# pse84_a0 register map
Vendor: Infineon Technologies; Series: PSE84_A0; File version: 1.0
CPU: CM33 r0p1, little endian, MPU, FPU, VTOR, 3 interrupt priority bits
Registers are 32-bit, read-write, reset 0x0 unless marked. A register's access mark holds for its fields unless they carry their own. Offsets are from the block's base; [hi:lo] are bit positions; lines under a group give offsets from that group; {n}, {i} and the like mark numbered series; <NAME> marks a mode.

## USBHS (part 3 of 7) — Regmap for both Subsystem and Controller IP
Base 0x44900000
0x00 DWC_OTG_INTREG group — Internal register map
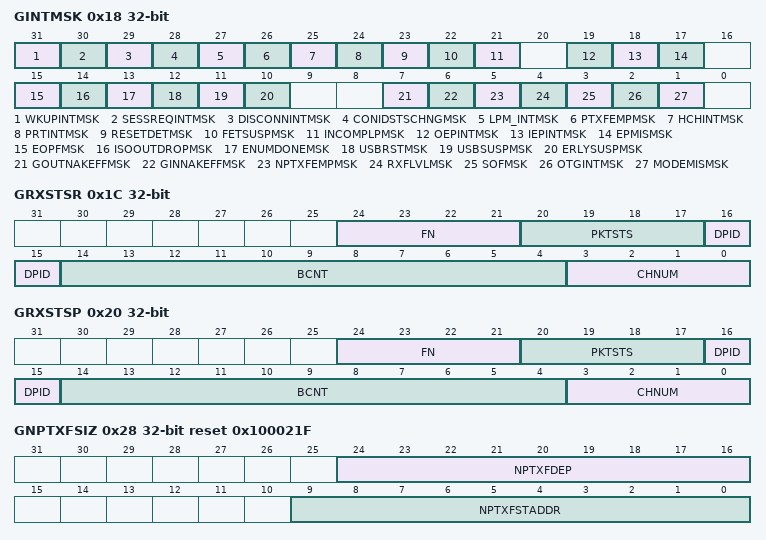
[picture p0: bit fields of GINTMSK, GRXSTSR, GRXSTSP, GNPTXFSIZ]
  0x18 GINTMSK — This register works with the Interrupt Register (GINTSTS) to interrupt the application. When an interrupt bit is masked, the interrupt associated with that bit is not generated. However, the GINTSTS register bit corresponding to that interrupt is still set. Note: The fields of this register change depending on host or device mode.
    [31] WKUPINTMSK — Mode: Host and Device Resume/Remote Wakeup Detected Interrupt Mask (WkUpIntMsk) The WakeUp bit is used for LPM state wake up in a way similar to that of wake up in suspend state.
      0=MASK (Resume or Remote Wakeup Detected Interrupt Mask); 1=NOMASK (Unmask Resume Remote Wakeup Detected Interrupt)
    [30] SESSREQINTMSK — Mode: Host and Device Session Request/New Session Detected Interrupt Mask (SessReqIntMsk)
      0=MASK (Session Request or New Session Detected Interrupt Mask); 1=NOMASK (No Session Request or New Session Detected Interrupt Mask)
    [29] DISCONNINTMSK — Mode: Host and Device Disconnect Detected Interrupt Mask (DisconnIntMsk)
      0=MASK (Disconnect Detected Interrupt Mask); 1=NOMASK (No Disconnect Detected Interrupt Mask)
    [28] CONIDSTSCHNGMSK — Mode: Host and Device Connector ID Status Change Mask (ConIDStsChngMsk)
      0=MASK (Connector ID Status Change Mask); 1=NOMASK (No Connector ID Status Change Mask)
    [27] LPM_INTMSK — Mode: Host and Device LPM Transaction Received Interrupt (LPM_Int) LPM Transaction received interrupt Mask
      0=MASK (LPM Transaction received interrupt Mask); 1=NOMASK (No LPM Transaction received interrupt Mask)
    [26] PTXFEMPMSK — Mode: Host only Periodic TxFIFO Empty Mask (PTxFEmpMsk)
      0=MASK (Periodic TxFIFO Empty Mask); 1=NOMASK (No Periodic TxFIFO Empty Mask)
    [25] HCHINTMSK — Mode: Host only Host Channels Interrupt Mask (HChIntMsk)
      0=MASK (Host Channels Interrupt Mask); 1=NOMASK (No Host Channels Interrupt Mask)
    [24] PRTINTMSK — Mode: Host only Host Port Interrupt Mask (PrtIntMsk)
      0=MASK (Host Port Interrupt Mask); 1=NOMASK (No Host Port Interrupt Mask)
    [23] RESETDETMSK — Mode: Device only Reset detected Interrupt Mask (ResetDetMsk)
      0=MASK (Reset detected Interrupt Mask); 1=NOMASK (No Reset detected Interrupt Mask)
    [22] FETSUSPMSK — Mode: Device only Data Fetch Suspended Mask (FetSuspMsk)
      0=MASK (Data Fetch Suspended Mask); 1=NOMASK (No Data Fetch Suspended Mask)
    [21] INCOMPLPMSK — Incomplete Periodic Transfer Mask (incomplPMsk) Mode: Host only Incomplete Isochronous OUT Transfer Interrupt Mask (incompISOOUTMsk) Mode: Device only
      0=MASK (<ct:cbc:1:0><br>Host mode: </ct>Incomplete Periodic Transfer Mask<ct:cbc:1:0><br>Device mode: Incomplete Isochronous OUT Transfer Mask</ct>); 1=NOMASK (<ct:cbc:1:0><br>Host mode: </ct>No Incomplete Periodic Transfer Mask<ct:cbc:1:0><br>Device mode: No Incomplete Isochronous OUT Transfer Mask</ct>)
    [19] OEPINTMSK — Mode: Device only OUT Endpoints Interrupt Mask (OEPIntMsk)
      0=MASK (OUT Endpoints Interrupt Mask); 1=NOMASK (No OUT Endpoints Interrupt Mask)
    [18] IEPINTMSK — Mode: Device only IN Endpoints Interrupt Mask (IEPIntMsk)
      0=MASK (IN Endpoints Interrupt Mask); 1=NOMASK (No IN Endpoints Interrupt Mask)
    [17] EPMISMSK — Mode: Device only Endpoint Mismatch Interrupt Mask (EPMisMsk)
      0=MASK (Endpoint Mismatch Interrupt Mask); 1=NOMASK (No Endpoint Mismatch Interrupt Mask)
    [15] EOPFMSK — Mode: Device only End of Periodic Frame Interrupt Mask (EOPFMsk)
      0=MASK (End of Periodic Frame Interrupt Mask); 1=NOMASK (No End of Periodic Frame Interrupt Mask)
    [14] ISOOUTDROPMSK — Mode: Device only Isochronous OUT Packet Dropped Interrupt Mask (ISOOutDropMsk)
      0=MASK (Isochronous OUT Packet Dropped Interrupt Mask); 1=NOMASK (No Isochronous OUT Packet Dropped Interrupt Mask)
    [13] ENUMDONEMSK — Mode: Device only Enumeration Done Mask (EnumDoneMsk)
      0=MASK (Enumeration Done Mask); 1=NOMASK (No Enumeration Done Mask)
    [12] USBRSTMSK — Mode: Device only USB Reset Mask (USBRstMsk)
      0=MASK (USB Reset Mask); 1=NOMASK (No USB Reset Mask)
    [11] USBSUSPMSK — Mode: Device only USB Suspend Mask (USBSuspMsk)
      0=MASK (USB Suspend Mask); 1=NOMASK (No USB Suspend Mask)
    [10] ERLYSUSPMSK — Mode: Device only Early Suspend Mask (ErlySuspMsk)
      0=MASK (Early Suspend Mask); 1=NOMASK (No Early Suspend Mask)
    [7] GOUTNAKEFFMSK — Mode: Device only Global OUT NAK Effective Mask (GOUTNakEffMsk)
      0=MASK (Global OUT NAK Effective Mask); 1=NOMASK (No Global OUT NAK Effective Mask)
    [6] GINNAKEFFMSK — Mode: Device only, Global Non-periodic IN NAK Effective Mask (GINNakEffMsk)
      0=MASK (Global Non-periodic IN NAK Effective Mask); 1=NOMASK (No Global Non-periodic IN NAK Effective Mask)
    [5] NPTXFEMPMSK — Mode: Host and Device Non-periodic TxFIFO Empty Mask (NPTxFEmpMsk)
      0=MASK (Non-periodic TxFIFO Empty Mask); 1=NOMASK (No Non-periodic TxFIFO Empty Mask)
    [4] RXFLVLMSK — Mode: Host and Device Receive FIFO Non-Empty Mask (RxFLvlMsk)
      0=MASK (Receive FIFO Non-Empty Mask); 1=NOMASK (No Receive FIFO Non-Empty Mask)
    [3] SOFMSK — Mode: Host and Device Start of (micro)Frame Mask (SofMsk)
      0=MASK (Start of Frame Mask); 1=NOMASK (No Start of Frame Mask)
    [2] OTGINTMSK — Mode: Host and Device OTG Interrupt Mask (OTGIntMsk)
      0=MASK (OTG Interrupt Mask); 1=NOMASK (No OTG Interrupt Mask)
    [1] MODEMISMSK — Mode: Host and Device Mode Mismatch Interrupt Mask (ModeMisMsk)
      0=MASK (Mode Mismatch Interrupt Mask); 1=NOMASK (No Mode Mismatch Interrupt Mask)
  0x1C GRXSTSR ro — A read to the Receive Status Debug Read register returns the contents of the top of the Receive FIFO. The receive status contents must be interpreted differently in Host and Device modes. The core ignores the receive status read when the receive FIFO is empty and returns a value of 32'h0000_0000. Note: - Use of these fields vary based on whether the core is functioning as a host or a device. - Do not read this register's reset value before configuring the core because the read value is 'X' in the simulation.
    [24:21] FN — Mode: Device only Frame Number (FN) This is the least significant 4 bits of the (micro)Frame number in which the packet is received on the USB. This field is supported only when isochronous OUT endpoints are supported.
    [20:17] PKTSTS
      7=CHHALT (Channel halted in host mode (triggers an interrupt)); 4=DSETUPCOM (SETUP transaction completed <ct:DWC_DESIGN_ID==0>in device mode </ct>(triggers an interrupt)); 6=DSETUPRX (SETUP data packet received<ct:DWC_DESIGN_ID==0> in device mode</ct>); 5=DTTOG (Data toggle error (triggers an interrupt) in host mode); 2=INOUTDPRX (<ct:DWC_DESIGN_ID==0>IN data packet received in host mode and </ct>OUT data packet received <ct:DWC_DESIGN_ID==0>in device mode</ct>); 3=INOUTTRCOM (IN or OUT transfer completed <ct:DWC_DESIGN_ID==0>in both host and device mode </ct>(triggers an interrupt)); 1=OUTNAK (Global OUT NAK <ct:DWC_DESIGN_ID==0>in device mode </ct>(triggers an interrupt))
    [16:15] DPID — Data PID (DPID) In host mode, indicates the Data PID of the received packet. In device mode, indicates the Data PID of the received OUT data packet. - 2'b00: DATA0 - 2'b10: DATA1 - 2'b01: DATA2 - 2'b11: MDATA Reset: 2'h0
      0=DATA0; 2=DATA1; 1=DATA2; 3=MDATA
    [14:4] BCNT — Byte Count (BCnt) In host mode, indicates the byte count of the received IN data packet. In device mode, indicates the byte count of the received data packet.
    [3:0] CHNUM — Channel Number (ChNum) Mode: Host only Indicates the channel number to which the current received packet belongs. Endpoint Number (EPNum) Mode: Device only Indicates the endpoint number to which the current received packet belongs.
      {v}=CHEP{v} (Channel or EndPoint {v}) (v=0..15)
  0x20 GRXSTSP ro — A read to the Receive Status Read and Pop register returns the contents of the top of the Receive FIFO and additionally pops the top data entry out of the RxFIFO. The receive status contents must be interpreted differently in Host and Device modes. The core ignores the receive status pop/read when the receive FIFO is empty and returns a value of 32'h0000_0000. The application must only pop the Receive Status FIFO when the Receive FIFO Non-Empty bit of the Core Interrupt register (GINTSTS.RxFLvl) is asserted. Note: - Use of these fields vary based on whether the core is functioning as a host or a device. - Do not read this register's reset value before configuring the core because the read value is 'X' in the simulation.
    [24:21] FN — Mode: Device only Frame Number (FN) This is the least significant 4 bits of the (micro)Frame number in which the packet is received on the USB. This field is supported only when isochronous OUT endpoints are supported.
    [20:17] PKTSTS
      4=DSETUPCOM (SETUP transaction completed <ct:DWC_DESIGN_ID==0>in device mode </ct>(triggers an interrupt)); 5=DTTOG (Data toggle error (triggers an interrupt) in host mode); 2=INOUTDPRX (<ct:DWC_DESIGN_ID==0>IN data packet received in host mode and </ct>OUT data packet received <ct:DWC_DESIGN_ID==0>in device mode</ct>); 3=INOUTTRCOM (IN or OUT transfer completed <ct:DWC_DESIGN_ID==0>in both host and device mode </ct>(triggers an interrupt)); 1=OUTNAK (Global OUT NAK <ct:DWC_DESIGN_ID==0>in device mode </ct>(triggers an interrupt))
    [16:15] DPID — Data PID (DPID) In host mode, indicates the Data PID of the received packet. In device mode, indicates the Data PID of the received OUT data packet. - 2'b00: DATA0 - 2'b10: DATA1 - 2'b01: DATA2 - 2'b11: MDATA Reset: 2'h0
      0=DATA0; 2=DATA1; 1=DATA2; 3=MDATA
    [14:4] BCNT — Byte Count (BCnt) In host mode, indicates the byte count of the received IN data packet. In device mode, indicates the byte count of the received data packet.
    [3:0] CHNUM — Channel Number (ChNum) Mode: Host only Indicates the channel number to which the current received packet belongs. Endpoint Number (EPNum) Mode: Device only Indicates the endpoint number to which the current received packet belongs.
      {v}=CHEP{v} (Channel or EndPoint {v}) (v=0..15)
  0x24 GRXFSIZ reset 0x21F — The application can program the RAM size that must be allocated to the RxFIFO.
    [9:0] RXFDEP — Mode: Host and Device RxFIFO Depth (RxFDep) This value is in terms of 32-bit words. - Minimum value is 16 - Maximum value is 32,768 The power-on reset value of this register is specified as the Largest Rx Data FIFO Depth during configuration. If Enable Dynamic FIFO Sizing is selected in coreConsultant, these flops are optimized, and reads return the power-on value. If Enable Dynamic FIFO Sizing is selected in coreConsultant, you can write a new value in this field. Programmed values must not exceed the power-on value.
  0x28 GNPTXFSIZ reset 0x100021F — The application can program the RAM size and the memory start address for the Non-periodic TxFIFO Note: The fields of this register change depending on host or device mode.
    [24:16] NPTXFDEP — Mode: Host only Non-periodic TxFIFO Depth (NPTxFDep) For host mode, this field is always valid. For device mode, this field is valid only when OTG_EN_DED_TX_FIFO=0. This value is in terms of 32-bit words. - Minimum value is 16 - Maximum value is 32,768 This attribute of field is determined during coreConsultant configuration by 'Enable Dynamic FIFO Sizing?' (OTG_DFIFO_DYNAMIC): - OTG_DFIFO_DYNAMIC = 0: These flops are optimized, and reads return the power-on value. - OTG_DFIFO_DYNAMIC = 1: The application can write a new value in this field. Programmed values must not exceed the power-on value set in coreConsultant. The power-on reset value of this field is specified during coreConsultant configuration as Largest IN Endpoint FIFO 0 Depth (parameter OTG_TX_DINEP_DFIFO_DEPTH_0).
    [9:0] NPTXFSTADDR — Non-periodic Transmit RAM Start Address (NPTxFStAddr) For host mode, this field is always valid. This field contains the memory start address for Non-periodic Transmit FIFO RAM. - This field is determined during coreConsultant configuration by 'Enable Dynamic FIFO Sizing?' (OTG_DFIFO_DYNAMIC):OTG_DFIFO_DYNAMIC = 0 These flops are optimized, and reads return the power-on value. - OTG_DFIFO_DYNAMIC = 1 The application can write a new value in this field. Programmed values must not exceed the power-on value set in coreConsultant. Programmed values must not exceed the power-on value set in coreConsultant. The power-on reset value of this field is specified during coreConsultant configuration by Largest Rx Data FIFO Depth (parameter OTG_RX_DFIFO_DEPTH).
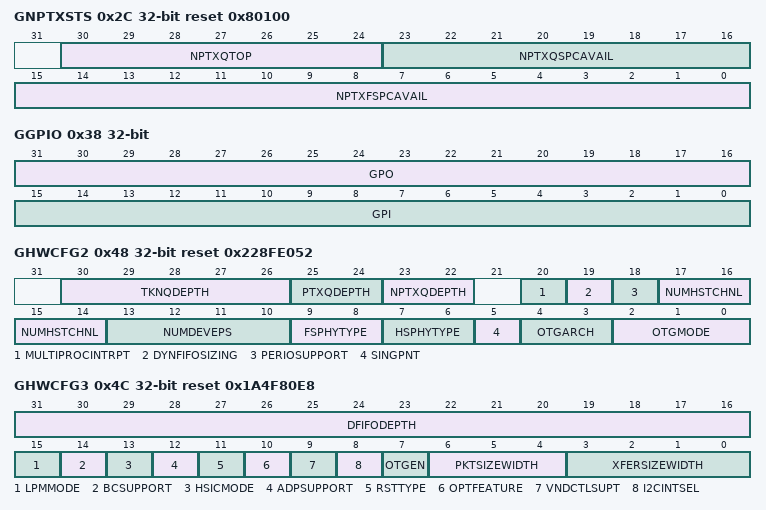
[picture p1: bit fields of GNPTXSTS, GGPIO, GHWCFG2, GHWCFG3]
  0x2C GNPTXSTS ro reset 0x80100 — In Device mode, this register is valid only in Shared FIFO operation. This read-only register contains the free space information for the Non-periodic TxFIFO and the Non-periodic Transmit Request Queue.
    [30:24] NPTXQTOP — Top of the Non-periodic Transmit Request Queue (NPTxQTop) Entry in the Non-periodic Tx Request Queue that is currently being processed by the MAC. - Bits [30:27]: Channel/endpoint number - Bits [26:25]: - 2'b00: IN/OUT token -- 2'b01: Zero-length transmit packet (device IN/host OUT) -- 2'b10: PING/CSPLIT token -- 2'b11: Channel halt command - Bit [24]: Terminate (last Entry for selected channel/endpoint) Reset: 7'h0
    [23:16] NPTXQSPCAVAIL
    [15:0] NPTXFSPCAVAIL
  0x38 GGPIO — The application can use this register for general purpose input/output ports or for debugging.
    [31:16] GPO — General Purpose Output (GPO) This field is driven as an output from the core, gp_o[15:0]. The application can program this field to determine the corresponding value on the gp_o[15:0] output.
    [15:0] GPI ro — General Purpose Input (GPI) This field's read value reflects the gp_i[15:0] core input value.
  0x3C GUID reset 0x12345678 — This is a read/write register containing the User ID. It is implemented only if Remove Optional Features? was deselected during coreConsultant configuration (parameter OTG_RM_OPT_FEATURES = 0). The power-on value for this register is specified as the Power-on Value of User ID Register User Identification Register during coreConsultant configuration (parameter OTG_USERID). This register can be used in the following ways: - To store the version or revision of your system - To store hardware configurations that are outside the DWC_otg core - As a scratch register
    [31:0] GUID — User ID (UserID) Application-programmable ID field. Reset value is configurable.
  0x40 GSNPSID ro reset 0x4F54420A — This read-only register contains the release number of the core being used.
    [31:0] SYNOPSYSID — Release number of the controller being used currently. Bits [31:16]: - 0x4f54: ASCII Value for OT Bits [15:0]: Current Release Number. For example, 0x400a corresponds to v4.00a Release number.
  0x44 GHWCFG1 ro — This register contains the logical endpoint direction(s) selected using coreConsultant.
    [31:0] EPDIR
  0x48 GHWCFG2 ro reset 0x228FE052 — This register contains configuration options selected using coreConsultant.
    [30:26] TKNQDEPTH — Device Mode IN Token Sequence Learning Queue Depth (TknQDepth) Range: 0-30 Note: This field is configured using the OTG_TOKEN_QUEUE_DEPTH parameter.
    [25:24] PTXQDEPTH — Host Mode Periodic Request Queue Depth (PTxQDepth) - 2'b00: 2 - 2'b01: 4 - 2'b10: 8 - 2'b11:16 Note: This field is configured using the OTG_PERIO_TX_QUEUE_DEPTH parameter.
      3=QUE16 (Queue Depth 16); 0=QUE2 (Queue Depth 2); 1=QUE4 (Queue Depth 4); 2=QUE8 (Queue Depth 8)
    [23:22] NPTXQDEPTH
      2=EIGHT (Queue size 8); 1=FOUR (Queue size 4); 0=TWO (Queue size 2)
    [20] MULTIPROCINTRPT — Multi Processor Interrupt Enabled (MultiProcIntrpt) - 1'b0: No - 1'b1: Yes Note: This field is configured using the OTG_MULTI_PROC_INTRPT parameter.
      0=DISABLED (No Multi Processor Interrupt Enabled); 1=ENABLED (Multi Processor Interrupt Enabled)
    [19] DYNFIFOSIZING — Dynamic FIFO Sizing Enabled (DynFifoSizing) - 1'b0: No - 1'b1: Yes Note: This field is configured using the OTG_DFIFO_DYNAMIC parameter.
      0=DISABLED (Dynamic FIFO Sizing Disabled); 1=ENABLED (Dynamic FIFO Sizing Enabled)
    [18] PERIOSUPPORT — Periodic OUT Channels Supported in Host Mode (PerioSupport) - 1'b0: No - 1'b1: Yes Note: This field is configured using the OTG_EN_PERIO_HOST parameter.
      0=DISABLED (Periodic OUT Channels is not supported in Host Mode); 1=ENABLED (Periodic OUT Channels Supported in Host Mode Supported)
    [17:14] NUMHSTCHNL — Number of Host Channels (NumHstChnl) Indicates the number of host channels supported by the core in Host mode. The range of this field is 0-15: 0 specifies 1 channel, 15 specifies 16 channels. Note: This field is configured using the OTG_NUM_HOST_CHAN parameter.
      {v}=HOSTCH{v} (Host Channel {v+1}) (v=0..15)
    [13:10] NUMDEVEPS — Number of Device Endpoints (NumDevEps) Indicates the number of device endpoints supported by the core in Device mode. The range of this field is 0-15. Note: This field is configured using the OTG_NUM_EPS parameter.
      {v}=ENDPT{v} (End point {v}) (v=0..15)
    [9:8] FSPHYTYPE — Full-Speed PHY Interface Type (FSPhyType) - 2'b00: Full-speed interface not supported - 2'b01: Dedicated full-speed interface - 2'b10: FS pins shared with UTMI+ pins - 2'b11: FS pins shared with ULPI pins Note: This field is configured using the OTG_FSPHY_INTERFACE parameter.
      1=FS (Dedicated full-speed interface is supported); 3=FSPLUSULPI (FS pins shared with ULPI pins is supported); 2=FSPLUSUTMI (FS pins shared with UTMI+ pins is supported); 0=NO_FS (Full-speed interface not supported)
    [7:6] HSPHYTYPE — High-Speed PHY Interface Type (HSPhyType) - 2'b00: High-Speed interface not supported - 2'b01: UTMI+ - 2'b10: ULPI - 2'b11: UTMI+ and ULPI Note: This field is configured using the OTG_HSPHY_INTERFACE parameter.
      0=NOHS (High-Speed interface not supported); 2=ULPI (High Speed Interface ULPI is supported); 1=UTMIPLUS (High Speed Interface UTMI+ is supported); 3=UTMIPUSULPI (High Speed Interfaces UTMI+ and ULPI is supported)
    [5] SINGPNT — Point-to-Point (SingPnt) - 1'b0: Multi-point application (hub and split support) - 1'b1: Single-point application (no hub and split support) Note: This field is configured using the OTG_SINGLE_POINT parameter.
      0=MULTIPOINT (Multi-point application (hub and split support)); 1=SINGLEPOINT (Single-point application (no hub and split support))
    [4:3] OTGARCH
      1=EXTERNALDMA (External DMA Mode); 2=INTERNALDMA (Internal DMA Mode); 0=SLAVEMODE
    [2:0] OTGMODE
      0=HNPSRP (HNP- and SRP-Capable OTG (Host and Device)); 2=NHNPNSRP (Non-HNP and Non-SRP Capable OTG (Host and Device)); 4=NONOTGD (Non-OTG Device); 6=NONOTGH (Non-OTG Host); 3=SRPCAPD (SRP-Capable Device); 5=SRPCAPH (SRP-Capable Host); 1=SRPOTG (SRP-Capable OTG (Host and Device))
  0x4C GHWCFG3 ro reset 0x1A4F80E8 — This register contains configuration options selected using coreConsultant.
    [31:16] DFIFODEPTH — DFIFO Depth (DfifoDepth - EP_LOC_CNT) This value is in terms of 32-bit words. - Minimum value is 32 - Maximum value is 32,768 Note: This field is configured using the OTG_DFIFO_DEPTH parameter. For more information on EP_LOC_CNT, see the 'Endpoint Information Controller (EPINFO_CTL)' section.
    [15] LPMMODE — LPM mode specified for Mode of Operation.
      0=DISABLED (LPM disabled); 1=ENABLED (LPM enabled)
    [14] BCSUPPORT — This bit indicates the controller support for Battery Charger. - 0 - No Battery Charger Support - 1 - Battery Charger support present
      0=DISABLED (No Battery Charger Support); 1=ENABLED (Battery Charger Support present)
    [13] HSICMODE — HSIC mode specified for Mode of Operation Value Range: 0 - 1 - 1: HSIC-capable with shared UTMI PHY interface - 0: Non-HSIC-capable
      0=DISABLED (No HSIC capability); 1=ENABLED (HSIC-capable with shared UTMI PHY interface)
    [12] ADPSUPPORT — This bit indicates whether ADP logic is present within or external to the controller - 0: No ADP logic present with the controller - 1: ADP logic is present along with the controller.
      0=DISABLED (ADP logic is not present along with the controller); 1=ENABLED (ADP logic is present along with the controller)
    [11] RSTTYPE — Reset Style for Clocked always Blocks in RTL (RstType) - 1'b0: Asynchronous reset is used in the controller - 1'b1: Synchronous reset is used in the controller Note: This field is configured using the OTG_SYNC_RESET_TYPE parameter.
      0=ASYNCRST (Asynchronous reset is used in the core); 1=SYNCRST (Synchronous reset is used in the core)
    [10] OPTFEATURE — Optional Features Removed (OptFeature) Indicates whether the User ID register, GPIO interface ports, and SOF toggle and counter ports were removed for gate count optimization by enabling Remove Optional Features. - 1'b0: No - 1'b1: Yes Note: This field is configured using the OTG_RM_OPT_FEATURES parameter.
      0=DISABLED (Optional features were not Removed); 1=ENABLED (Optional Features have been Removed)
    [9] VNDCTLSUPT — Vendor Control Interface Support (VndctlSupt) - 1'b0: Vendor Control Interface is not available on the core. - 1'b1: Vendor Control Interface is available. Note: This field is configured using the OTG_VENDOR_CTL_INTERFACE parameter.
      0=DISABLED (Vendor Control Interface is not available.); 1=ENABLED (Vendor Control Interface is available.)
    [8] I2CINTSEL — I2C Selection (I2CIntSel) - 1'b0: I2C Interface is not available on the controller. - 1'b1: I2C Interface is available on the controller. Note: This field is configured using the OTG_I2C_INTERFACE parameter.
      0=DISABLED (I2C Interface is not available); 1=ENABLED (I2C Interface is available)
    [7] OTGEN — OTG Function Enabled (OtgEn) The application uses this bit to indicate the OTG capabilities of the controller . - 1'b0: Not OTG capable - 1'b1: OTG Capable Note: This field is configured using the OTG_MODE parameter.
      0=DISABLED (Not OTG Capable); 1=ENABLED (OTG Capable)
    [6:4] PKTSIZEWIDTH
      {v}=BITS{v+4} (Width of Packet Size Counter {v+4}) (v=0..6)
    [3:0] XFERSIZEWIDTH
      {v}=WIDTH{v+11} (Width of Transfer Size Counter {v+11} bits) (v=0..8)
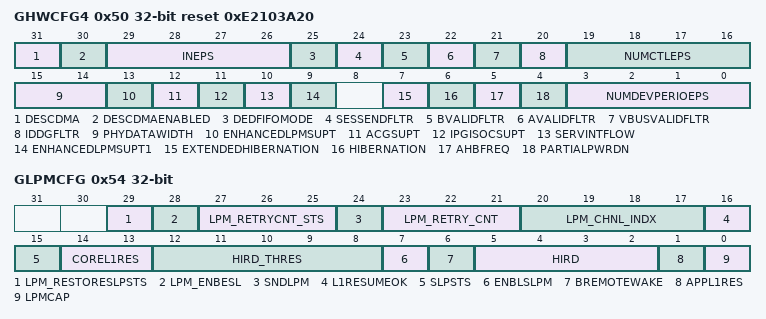
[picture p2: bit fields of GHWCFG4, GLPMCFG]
  0x50 GHWCFG4 ro reset 0xE2103A20
    [31] DESCDMA — Scatter/Gather DMA configuration - 1'b0: Non Dynamic configuration - 1'b1: Dynamic configuration Note: This field is configured using the OTG_EN_DESC_DMA parameter.
      0=CONFIG1 (Non Dynamic configuration); 1=CONFIG2 (Dynamic configuration)
    [30] DESCDMAENABLED — Scatter/Gather DMA configuration - 1'b0: Non-Scatter/Gather DMA configuration - 1'b1: Scatter/Gather DMA configuration
      0=DISABLE (Non-Scatter/Gather DMA configuration); 1=ENABLE (Scatter/Gather DMA configuration)
    [29:26] INEPS — Number of Device Mode IN Endpoints Including Control Endpoints (INEps) - 0: 1 IN Endpoint - 1: 2 IN Endpoints .... - 15: 16 IN Endpoints
      0=ENDPT1 (1 IN Endpoint); {v}=ENDPT{v+1} ({v+1} IN Endpoints) (v=1..15)
    [25] DEDFIFOMODE — Enable Dedicated Transmit FIFO for device IN Endpoints (DedFifoMode) - 1'b0 : Dedicated Transmit FIFO Operation not enabled. - 1'b1 : Dedicated Transmit FIFO Operation enabled.
      0=DISABLED (Dedicated Transmit FIFO Operation not enabled); 1=ENABLED (Dedicated Transmit FIFO Operation enabled)
    [24] SESSENDFLTR — session_end Filter Enabled (SessEndFltr) - 1'b0: No filter - 1'b1: Filter
      0=DISABLED (No filter); 1=ENABLED (Filter)
    [23] BVALIDFLTR — b_valid Filter Enabled (BValidFltr) - 1'b0: No filter - 1'b1: Filter
      0=DISABLED (No Filter); 1=ENABLED (Filter)
    [22] AVALIDFLTR — a_valid Filter Enabled (AValidFltr) - 1'b0: No filter - 1'b1: Filter
      0=DISABLED (No filter); 1=ENABLED (Filter)
    [21] VBUSVALIDFLTR — VBUS Valid Filter Enabled (VBusValidFltr) - 1'b0: No filter - 1'b1: Filter
      0=DISABLED (Vbus Valid Filter Disabled); 1=ENABLED (Vbus Valid Filter Enabled)
    [20] IDDGFLTR — IDDIG Filter Enable (IddgFltr) - 1'b0: No filter - 1'b1: Filter
      0=DISABLED (Iddig Filter Disabled); 1=ENABLED (Iddig Filter Enabled)
    [19:16] NUMCTLEPS — Number of Device Mode Control Endpoints in Addition to Endpoint 0 (NumCtlEps) Range: 0-15
      {v}=ENDPT{v} (End point {v}) (v=0..15)
    [15:14] PHYDATAWIDTH
      0=WIDTH1 (8 bits); 1=WIDTH2 (16 bits); 2=WIDTH3 (8/16 bits, software selectable)
    [13] ENHANCEDLPMSUPT — Enhanced LPM Support (EnhancedLPMSupt) This bit indicates that the controller supports the following behavior: L1 Entry Behavior based on FIFO Status - TX FIFO - Accept L1 Request even if ISOC IN TX FIFO is not empty. - Reject L1 Request if Non-Periodic TX FIFO is not empty. - Ensure application can flush the TX FIFO while the Controller is in L1. - RX FIFO - Accept L1 Request even if RX FIFO (common to Periodic and Non-Periodic) is not empty. - Accept L1 Request but delay SLEEPM assertion until RX SINK Buffer is empty. Prevent L1 Entry if a Control Transfer is in progress on any Control Endpoint. Ability to Flush TxFIFO even if PHY Clock is gated.
      1=ENABLED (Enhanced LPM Support is enabled)
    [12] ACGSUPT — Active Clock Gating Support This bit indicates that the controller supports the Dynamic (Switching) Power Reduction during periods when there is no USB and AHB Traffic. - 1'b0: Active Clock Gating is not enabled. - 1'b1: Active Clock Gating Enabled.
      0=DISABLED (N/A); 1=ENABLED (Active Clock Gating Support)
    [11] IPGISOCSUPT — Interpacket Gap ISOC OUT Worst-case Support (ipgisocSupt) This bit indicates that the controller supports the worst-case scenario of Rx followed by Rx Inter Packet Gap (IPG) (32-bit times) as per the UTMI Specification for any token following an ISOC OUT token. Without this support, when any token follows an ISOC OUT token with the worst-case IPG, the controller will not detect the followed token. The worst-case IPG of the controller without this support depends on the AHB and PHY clock frequency.By default IPG Support is enabled.
      0=DISABLED (Interpacket Gap ISOC OUT Worst-case Support is Disabled); 1=ENABLED (Interpacket Gap ISOC OUT Worst-case Support is Enabled (Default))
    [10] SERVINTFLOW — Service Interval Flow This bit indicates that the controller supports Service-Interval based scheduling flow for ISOC IN EPs.
      0=DISABLED (Service Interval Flow not supported); 1=ENABLED (Service Interval Flow supported)
    [9] ENHANCEDLPMSUPT1 — Enhanced LPM Support1 (EnhancedLPMSupt1) - This bit indicates that the controller supports L1 entry based on FIFO status. - Accept L1 Request even if Bulk/Interrupt TxFIFO is not empty.
      0=DISABLED (Reject L1 Request even if Non-Periodic (Bulk/Interrupt) TxFIFO is not empty.); 1=ENABLED (Accept L1 Request even if Non-Periodic (Bulk/Interrupt) TxFIFO is not empty)
    [7] EXTENDEDHIBERNATION — Enable Hibernation - 1'b0: Extended Hibernation feature not enabled - 1'b1: Extended Hibernation feature enabled
      0=DISABLED (Extended Hibernation feature not enabled); 1=ENABLED (Extended Hibernation feature enabled)
    [6] HIBERNATION — Enable Hibernation (Hibernation) - 1'b0: Hibernation feature not enabled - 1'b1: Hibernation feature enabled
      0=DISABLED (Hibernation feature disabled); 1=ENABLED (Hibernation feature enabled)
    [5] AHBFREQ — Minimum AHB Frequency Less Than 60 MHz (AhbFreq) - 1'b0: No - 1'b1: Yes
      0=DISABLED (Minimum AHB Frequency More Than 60 MHz); 1=ENABLED (Minimum AHB Frequency Less Than 60 MHz)
    [4] PARTIALPWRDN — Enable Partial Power Down (PartialPwrDn) - 1'b0: Partial Power Down Not Enabled - 1'b1: Partial Power Down Enabled
      0=DISABLED (Partial Power Down disabled); 1=ENABLED (Partial Power Down enabled)
    [3:0] NUMDEVPERIOEPS — Number of Device Mode Periodic IN Endpoints (NumDevPerioEps) Range: 0-15
      {v}=Number of Periodic IN EPs is {v} (v=0..15)
  0x54 GLPMCFG — Register to control the LPM functionality of the controller.
    [29] LPM_RESTORESLPSTS — LPM Restore Sleep Status (LPM_RestoreSlpSts) When the application power gates the core (Partial Power Down / Hibernation) the application needs to program this bit to restore the LPM status in the core. The application needs to program this bit, during restore process, based on whether it had decided to go into Shallow Sleep (Clock Gating Only) or Deep Sleep (Power Gating) based on the BESL value received from the Host - 1'b0: The application puts the core in Shallow Sleep based on BESL value from the Host - 1'b1: The application puts the core in Deep Sleep based on BESL value from the Host
      0=DISABLED (Puts the core in Shallow Sleep mode based on the BESL value from the Host); 1=ENABLED (Puts the core in Deep Sleep mode based on the BESL value from the Host)
    [28] LPM_ENBESL — LPM Enable BESL (LPM_EnBESL) This bit enables the BESL feature as defined in LPM Errata - 1'b0: The core works as per USB 2.0 Link Power Management Addendum Engineering Change Notice to the USB 2.0 specification as of July 16, 2007 - 1'b1: The core works as per the LPM Errata
      0=DISABLED (BESL is disabled); 1=ENABLED (BESL is enabled as defined in LPM Errata)
    [27:25] LPM_RETRYCNT_STS ro — LPM Retry Count Status (LPM_RetryCnt_Sts) Host Mode: Number of LPM Host Retries still remaining to be transmitted for the current LPM sequence.
      0=RETRY_REM0 (Zero LPM retries remaining); 1=RETRY_REM1 (One LPM retry remaining); 2=RETRY_REM2 (Two LPM retries remaining); 3=RETRY_REM3 (Three LPM retries remaining); 4=RETRY_REM4 (Four LPM retries remaining); 5=RETRY_REM5 (Five LPM retries remaining); 6=RETRY_REM6 (Six LPM retries remaining); 7=RETRY_REM7 (Seven LPM retries remaining)
    [24] SNDLPM — Send LPM Transaction (SndLPM) Host Mode: When set by application software, an LPM transaction containing two tokens, EXT & LPM is sent. Cleared by the hardware once a valid response (STALL./NYET/ACK) is received from the Device or the core had finished transmitting the programmed number of LPM retries. Note that this bit should be set only when the host is connected to local port.
      0=DISABLED (In host-only mode: Received the response from the device for the LPM transaction); 1=ENABLED (In host-only mode: Sending LPM transaction containing EXT and LPM tokens)
    [23:21] LPM_RETRY_CNT — LPM Retry Count (LPM_Retry_Cnt) Host Mode: Number of additional LPM retries that the HOST would perform if the Device Response was an ERROR until a valid device response is received (STALL/NYET/ACK). Device Mode: LPM Accept Control (LPM_Accept_Ctrl) LPM_Accept_Ctrl[1]: The application can use this bit to reject an LPM token (NYET) between multiple stages of a single control transfer - 1'b0: Accept(ACK) LPM token during Setup, Data and Status stage of control transfer. - 1'b1: Reject(NYET) LPM token during Setup, Data and Status stage of control transfer. LPM_Accept_Ctrl[2]: The application can use this bit to accept an LPM token even if data is present in the ISOC endpoint TxFIFO. This bit is applicable only for Dedicated TxFIFO configurations (OTG_EN_DED_TX_FIFO=1). - 1'b0: Reject (NYET) LPM token, when data is present in TxFIFO for ISOC endpoints. - 1'b1: Accept(ACK) LPM token, when data is present in TxFIFO for ISOC endpoints. LPM_Accept_Ctrl[3]: The application can use this bit to accept an LPM token even if data is present in the BULK endpoint TxFIFO. This bit is applicable only for Dedicated TxFIFO configurations (OTG_EN_DED_TX_FIFO=1). - 1'b0: Reject (NYET) LPM token, when data is present in TxFIFO for BULK endpoints. - 1'b1: Accept(ACK) LPM token, when data is present in TxFIFO for BULK endpoints.
      0=RETRY0 (Zero LPM retries); 1=RETRY1 (One LPM retry); 2=RETRY2 (Two LPM retries); 3=RETRY3 (Three LPM retries); 4=RETRY4 (Four LPM retries); 5=RETRY5 (Five LPM retries); 6=RETRY6 (Six LPM retries); 7=RETRY7 (Seven LPM retries)
    [20:17] LPM_CHNL_INDX — LPM Channel Index Host Mode: The channel number on which the LPM transaction has to be applied while sending an LPM transaction to the local device. Based on the LPM channel index, the core automatically inserts the device address and end point number programmed in the corresponding channel into the LPM transaction. Device Mode: LPM Accept Control (LPM_Accept_Ctrl) LPM_Accept_Ctrl[0] (LPM_Chnl_Indx[3]): The application can use this bit to accept an LPM token even if data is present in the INTR endpoint TxFIFO. This bit is applicable only for Dedicated TX FIFO configurations (OTG_EN_DED_TX_FIFO=1). - 1'b0:Reject (NYET) LPM token, when data is present in txfifo for INTR endpoints. - 1'b1:Accept(ACK) LPM token, when data is present in txfifo for INTR endpoints.
      {v}=CH{v} (Channel {v}) (v=0..14); 15=CH15 (Channel15)
    [16] L1RESUMEOK ro — Sleep State Resume OK (L1ResumeOK) Device and Host Mode: Indicates that the application or host can start resume from Sleep state. This bit is valid in LPM sleep (L1) state. It is set in sleep mode after a delay of 50 micro sec (TL1Residency). The bit is reset when SlpSts is 0. - 1'b0: The application/core cannot start resume from Sleep state. - 1'b1: The application/core can start resume from Sleep state.
      0=NOTOK (The application/core cannot start Resume from Sleep state); 1=OK (The application/core can start Resume from Sleep state)
    [15] SLPSTS ro — Port Sleep Status (SlpSts) Device Mode: This bit is set as long as a Sleep condition is present on the USB bus. The core enters the Sleep state when an ACK response is sent to an LPM transaction and the TL1TokenRetry timer has expired. To stop the PHY clock, the application must set the Port Clock Stop bit, which asserts the PHY Suspend input signal. The application must rely on SlpSts and not ACK in CoreL1Res to confirm transition into sleep. The core comes out of sleep: - When there is any activity on the USB line_state - When the application writes to the Remote Wakeup Signaling bit in the Device Control register (DCTL.RmtWkUpSig) or when the application resets or soft-disconnects the device. Host Mode: The host transitions to Sleep (L1) state as a side-effect of a successful LPM transaction by the core to the local port with ACK response from the device. The read value of this bit reflects the current Sleep status of the port. The core clears this bit after: - The core detects a remote L1 Wakeup signal; - The application sets the Port Reset bit or the Port L1Resume bit in the HPRT register; or - The application sets the L1Resume/ Remote Wakeup Detected Interrupt bit or Disconnect Detected Interrupt bit in the Core Interrupt register (GINTSTS.L1WkUpInt or GINTSTS.DisconnInt, respectively).
      1=CORE_IN_L1 (<ct:DWC_DESIGN_ID==0>In Host mode, this bit indicates the core transitions to Sleep state as a successful LPM transaction. </ct>In Device mode, the core enters the Sleep state when an ACK response is sent to an LPM transaction); 0=CORE_NOT_IN_L1 (In <ct:DWC_DESIGN_ID==0>Host or </ct>Device mode, this bit indicates core is not in L1)
    [14:13] COREL1RES ro — LPM Response (CoreL1Res) Device Mode: The response of the core to LPM transaction received is reflected in these two bits. Host Mode: Handshake response received from local device for LPM transaction - 11 - ACK - 10 - NYET - 01 - STALL - 00 - ERROR (No handshake response)
      0=LPMRESP1 (ERROR : No handshake response); 1=LPMRESP2 (STALL response); 2=LPMRESP3 (NYET response); 3=LPMRESP4 (ACK response)
    [12:8] HIRD_THRES — BESL/HIRD Threshold (HIRD_Thres) Device Mode: Note: When a ULPI/UTMI PHY associated with the controller (Host or device) does not support the LPM sleep feature clock gating, it is recommended to keep the HIRD_Thres[12] bit in disabled state (= 1'b0). This ensures the ULPI wrapper is in enabled mode and detects any wakeup events. - EnBESL = 1'b0: The core puts the PHY into deep low power mode in L1 (by core asserting L1SuspendM) when HIRD value is greater than or equal to the value defined in this field HIRD_Thres[3:0] and HIRD_Thres[4] is set to 1b1. - EnBESL = 1'b1: The core puts the PHY into deep low power mode in L1 (by core asserting L1SuspendM) when BESL value is greater than or equal to the value defined in this field BESL_Thres[3:0] and BESL_Thres [4] is set to 1'b1. - DCTL.DeepSleepBESLReject = 1'b1: In device initiated resume, the core expects the Host to resume service to the device within the BESL value corresponding to L1 exit time specified in HIRD_Thres[3:0]. The Device sends a NYET response when the received HIRD in LPM token is greater than HIRD threshold. Host Mode: The core puts the PHY into deep low power mode in L1 (by core asserting L1SuspendM) when HIRD_Thres[4] is set to 1'b1. HIRD_Thres[3:0] specifies the time for which resume signaling is to be reflected by host (TL1HubDrvResume2) on the USB bus when it detects device initiated resume. To differentiate between Deep Sleep and Shallow Sleep, HIRD greater than or equal to HIRD threshold comparison is done. For differentiating between NYET or ACK response for LPM token HIRD greater than HIRD Threshold comparison is used. - When EnBESL = 1'b0, HIRD_Thres should not be programmed with a value greater than 4'b1100 in host mode since this will exceed maximum TL1HubDrvResume2. - When EnBESL = 1'b1, HIRD_Thres should not be programmed with a value greater than 4'b0110 in host mode since this will exceed maximum TL1HubDrvResume2. For additional details, see the 'Additional Details on GLPMCFG.HIRD_Thres Register Field' section in the databook.
    [7] ENBLSLPM — Enable utmi_sleep_n (EnblSlpM) Mode: Host and Device For ULPI interface: The application uses this bit to control the utmi_sleep_n assertion to the PHY when in L1 state. For the host, this bit is valid only in Local Device mode. - 1'b0: utmi_sleep_n assertion from the core is not transferred to the external PHY. - 1'b1: utmi_sleep_n assertion from the core is transferred to the external PHY. Note: - When a ULPI interface is configured, enabling this bit results in a write to Bit 7 of the ULPI Function Control register. The Synopsys ULPI PHY supports writing to this bit, and in the L1 state asserts SleepM when utmi_l1_suspend_n cannot be asserted. - When a ULPI/UTMI PHY associated with the controller (Host or device) does not support the LPM sleep feature clock gating, it is recommended to keep the EnblSlpM bit in disabled state (= 1'b0). This ensures the ULPI wrapper is in enabled mode and detects any wakeup events. For all other interfaces: The application uses this bit to control utmi_sleep_n assertion to the PHY in the L1 state. For the host, this bit is valid only in Local Device mode. - 1'b0: utmi_sleep_n assertion from the core is not transferred to the external PHY. - 1'b1: utmi_sleep_n assertion from the core is transferred to the external PHY when utmi_l1_suspend_n cannot be asserted.
      0=DISABLED (utmi_sleep_n assertion from the core is not transferred to the external PHY); 1=ENABLED (utmi_sleep_n assertion from the core is transferred to the external PHY when utmi_l1_suspend_n cannot be asserted)
    [6] BREMOTEWAKE — RemoteWakeEnable (bRemoteWake) Mode: Host and Device Host Mode: The value of remote wake up to be sent in wIndex field of LPM transaction. Device Mode: This field is read only. It is updated with the Received LPM Token bRemoteWake bmAttribute when an ACK/NYET/STALL response is sent to an LPM transaction.
      0=DISABLED (Remote Wakeup is disabled); 1=ENABLED (In <ct:DWC_DESIGN_ID==0>Host or </ct>device mode, this field takes the value of remote wake up)
    [5:2] HIRD — Host-Initiated Resume Duration (HIRD) EnBESL = 1'b0 Host Initiated Resume Duration. - Host Mode: The value of HIRD to be sent in an LPM transaction. This value is also used to initiate resume for a duration TL1HubDrvResume1 for host-initiated resume. - Device Mode: This field is read only and is updated with the Received LPM Token HIRD bmAttribute when an ACK/NYET/STALL response is sent to an LPM transaction. If HIRD[3:0], - 4'b0000, THIRD(us) = 50 - 4'b0001, THIRD(us) = 125 - 4'b0010, THIRD(us) = 200 - 4'b0011, THIRD(us) = 275 - 4'b0100, THIRD(us) = 350 - 4'b0101, THIRD(us) = 425 - 4'b0110, THIRD(us) = 500 - 4'b0111, THIRD(us) = 575 - 4'b1000, THIRD(us) = 650 - 4'b1001, THIRD(us) = 725 - 4'b1010, THIRD(us) = 800 - 4'b1011, THIRD(us) = 875 - 4'b1100, THIRD(us) = 950 - 4'b1101, THIRD(us) = 1025 - 4'b1110, THIRD(us) = 1100 - 4'b1111, THIRD(us) = 1175 EnBESL = 1'b1 Best Effort Service Latency (BESL). - Host Mode: The value of BESL to be sent in an LPM transaction. This value is also used to initiate resume for a duration TL1HubDrvResume1 for host-initiated resume. - Device Mode: This field is updated with the Received LPM Token BESL bmAttribute when an ACK/NYET/STALL response is sent to an LPM transaction. If BESL[3:0], - 4'b0000, TBESL(us) = 125 - 4'b0001, TBESL(us) = 150 - 4'b0010, TBESL(us) = 200 - 4'b0011, TBESL(us) = 300 - 4'b0100, TBESL(us) = 400 - 4'b0101, TBESL(us) = 500 - 4'b0110, TBESL(us) = 1000 - 4'b0111, TBESL(us) = 2000 - 4'b1000, TBESL(us) = 3000 - 4'b1001, TBESL(us) = 4000 - 4'b1010, TBESL(us) = 5000 - 4'b1011, TBESL(us) = 6000 - 4'b1100, TBESL(us) = 7000 - 4'b1101, TBESL(us) = 8000 - 4'b1110, TBESL(us) = 9000 - 4'b1111, TBESL(us) = 10000
    [1] APPL1RES — Mode: Device only LPM response programmed by application (AppL1Res) Handshake response to LPM token pre-programmed by device application software. The response depends on GLPMCFG.LPMCap. If GLPMCFG.LPMCap is 1'b0, the core operates as a non-LPM-capable Device and does not respond to any LPM transactions. If GLPMCFG.LPMCap is 1'b1, the core responds as follows: - 1: ACK Even though an ACK is pre-programmed, the core responds with an ACK only on a successful LPM transaction. The LPM transaction is successful if: -- There are no PID/CRC5 errors in both the EXT token and the LPM token (else ERROR) -- A valid bLinkState = 0001B (L1) is received in the LPM transaction (else STALL) -- No data is pending in the Transmit queue (else NYET) - 0: NYET The pre-programmed software bit is overridden for response to LPM token when: -- The received bLinkState is not L1 (STALL response) -- An error is detected in either of the LPM token packets due to corruption (ERROR response).
      1=ACK_RESP (The core responds with an ACK only on a successful LPM transaction); 0=NYET_RESP (The core responds with a NYET when an error is detected in either of the LPM token packets due to corruption)
    [0] LPMCAP — LPM-Capable (LPMCap) The application uses this bit to control the controller LPM capabilities. If the core operates as a non-LPM-capable host, it cannot request the connected device/hub to activate LPM mode. If the core operates as a non-LPM-capable device, it cannot respond to any LPM transactions. If GLPMCFG.LPMCap is 1'b0, the software must not set any of the remaining fields in the GLPMCFG register and these fields should hold their Reset values. - 1'b0: LPM capability is not enabled. - 1'b1: LPM capability is enabled.
      0=DISABLED (LPM capability is not enabled); 1=ENABLED (LPM capability is enabled)
